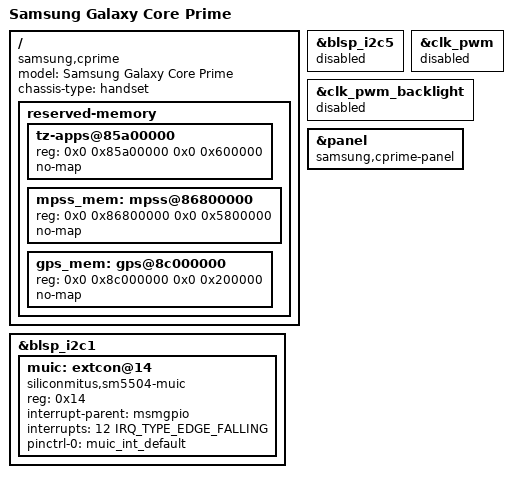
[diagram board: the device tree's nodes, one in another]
// SPDX-License-Identifier: GPL-2.0-only

/dts-v1/;

#include "msm8916-samsung-gprime-common.dtsi"

/ {
	model = "Samsung Galaxy Core Prime";
	compatible = "samsung,cprime", "qcom,msm8916";
	chassis-type = "handset";

	reserved-memory {
		/* Additional memory used by Samsung firmware modifications */
		tz-apps@85a00000 {
			reg = <0x0 0x85a00000 0x0 0x600000>;
			no-map;
		};

		mpss_mem: mpss@86800000 {
			reg = <0x0 0x86800000 0x0 0x5800000>;
			no-map;
		};

		gps_mem: gps@8c000000 {
			reg = <0x0 0x8c000000 0x0 0x200000>;
			no-map;
		};
	};
};

&blsp_i2c1 {
	/* SM5504 MUIC instead of SM5502 */
	/delete-node/ extcon@25;

	muic: extcon@14 {
	compatible = "siliconmitus,sm5504-muic";
		reg = <0x14>;
		interrupt-parent = <&msmgpio>;
		interrupts = <12 IRQ_TYPE_EDGE_FALLING>;
		pinctrl-names = "default";
		pinctrl-0 = <&muic_int_default>;
	};
};

&blsp_i2c5 {
	/* IST3038B touchscreen instead of BT541 */
	status = "disabled";
};

/* On cprime backlight is controlled with MIPI DCS commands */
&clk_pwm {
	status = "disabled";
};

&clk_pwm_backlight {
	status = "disabled";
};

&panel {
	/delete-property/ backlight;
	compatible = "samsung,cprime-panel";
};
